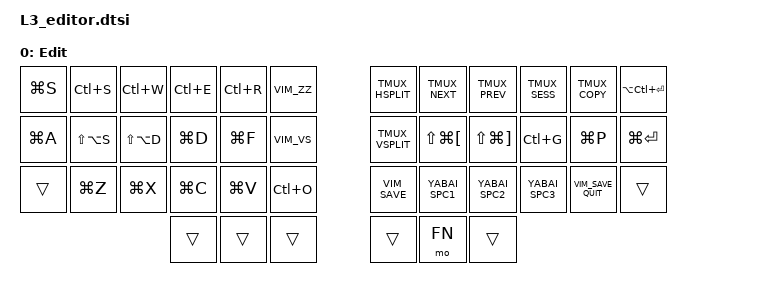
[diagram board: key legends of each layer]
/**
 * Code Editor Layer
 * Specialized for coding, vim, tmux, and advanced editing operations
 */

/ {
  keymap {
    compatible = "zmk,keymap";

    editor_layer {
      display-name = "Edit";
      bindings = <
// ╭───────────────┬───────────────┬───────────────┬───────────────┬───────────────┬───────────────╮   ╭───────────────┬───────────────┬───────────────┬───────────────┬───────────────┬───────────────╮
// │0              │1              │2              │3              │4              │5              │   │6              │7              │8              │9              │10             │11             │
    &kp LG(S)       &kp LC(S)       &kp LC(W)       &kp LC(E)       &kp LC(R)       &kp VIM_ZZ          &TMUX_HSPLIT    &TMUX_NEXT      &TMUX_PREV      &TMUX_SESS      &TMUX_COPY      &kp LA(LC(ENTER))
// ├───────────────├───────────────┼───────────────┼───────────────┼───────────────┼───────────────┤   ├───────────────├───────────────┼───────────────┼───────────────┼───────────────┼───────────────┤
// │12             │13             │14             │15             │16             │17             │   │18             │19             │20             │21             │22             │23             │
    &kp LG(A)       &kp LS(LA(S))   &kp LS(LA(D))   &kp LG(D)       &kp LG(F)       &kp VIM_VS          &TMUX_VSPLIT    &kp LS(LG(LBKT))&kp LS(LG(RBKT))&kp LC(G)       &kp LG(P)       &kp LG(ENTER)
// ├───────────────├───────────────┼───────────────┼───────────────┼───────────────┼───────────────┤   ├───────────────├───────────────┼───────────────┼───────────────┼───────────────┼───────────────┤
// │24             │25             │26             │27             │28             │29             │   │30             │31             │32             │33             │34             │35             │
    &trans          &kp LG(Z)       &kp LG(X)       &kp LG(C)       &kp LG(V)       &kp LC(O)            &VIM_SAVE       &kp YABAI_SPC1  &kp YABAI_SPC2  &kp YABAI_SPC3  &VIM_SAVE_QUIT   &trans
// ╰───────────────┴───────────────┴───────────────┼───────────────┼───────────────┼───────────────┤   ├───────────────├───────────────┼───────────────┼───────────────┴───────────────┴───────────────╯
//                                                 │36             │37             │38             │   │39             │40             │41             │
                                                    &trans          &trans          &trans              &trans          &mo FN          &trans
//                                                 ╰───────────────┴───────────────┴───────────────╯   ╰───────────────┴───────────────┴───────────────╯
      >;
    };
  };
};
